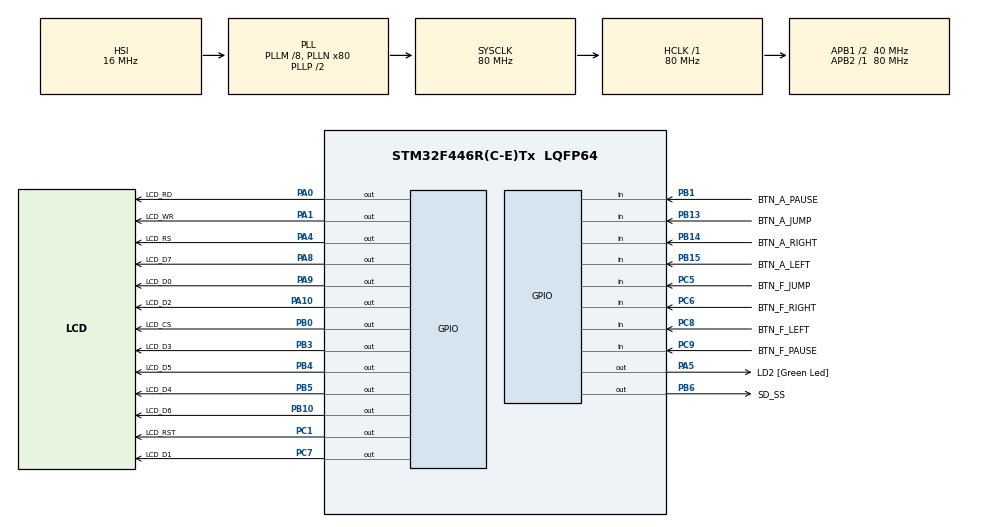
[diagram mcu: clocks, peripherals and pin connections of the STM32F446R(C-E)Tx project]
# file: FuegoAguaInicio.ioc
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Mcu.Family=STM32F4
Mcu.Name=STM32F446R(C-E)Tx
Mcu.Package=LQFP64
NVIC.PriorityGroup=NVIC_PRIORITYGROUP_0
PA0-WKUP.GPIO_Label=LCD_RD
PA0-WKUP.GPIO_Speed=GPIO_SPEED_FREQ_HIGH
PA0-WKUP.PinState=GPIO_PIN_SET
PA0-WKUP.Signal=GPIO_Output
PA1.GPIO_Label=LCD_WR
PA1.GPIO_Speed=GPIO_SPEED_FREQ_HIGH
PA1.PinState=GPIO_PIN_SET
PA1.Signal=GPIO_Output
PA10.GPIO_Label=LCD_D2
PA10.GPIO_Speed=GPIO_SPEED_FREQ_HIGH
PA10.Signal=GPIO_Output
PA13.GPIO_Label=TMS
PA13.Mode=Serial_Wire
PA13.Signal=SYS_JTMS-SWDIO
PA14.GPIO_Label=TCK
PA14.Mode=Serial_Wire
PA14.Signal=SYS_JTCK-SWCLK
PA2.GPIO_Label=USART_TX
PA2.Signal=USART2_TX
PA3.GPIO_Label=USART_RX
PA3.Signal=USART2_RX
PA4.GPIO_Label=LCD_RS
PA4.GPIO_Speed=GPIO_SPEED_FREQ_HIGH
PA4.Signal=GPIO_Output
PA5.GPIO_Label=LD2 [Green Led]
PA5.Signal=GPIO_Output
PA8.GPIO_Label=LCD_D7
PA8.GPIO_Speed=GPIO_SPEED_FREQ_HIGH
PA8.PinState=GPIO_PIN_RESET
PA8.Signal=GPIO_Output
PA9.GPIO_Label=LCD_D0
PA9.GPIO_Speed=GPIO_SPEED_FREQ_HIGH
PA9.Signal=GPIO_Output
PB0.GPIO_Label=LCD_CS
PB0.GPIO_Speed=GPIO_SPEED_FREQ_HIGH
PB0.PinState=GPIO_PIN_SET
PB0.Signal=GPIO_Output
PB1.GPIO_Label=BTN_A_PAUSE
PB1.GPIO_PuPd=GPIO_PULLUP
PB1.Signal=GPIO_Input
PB10.GPIO_Label=LCD_D6
PB10.GPIO_Speed=GPIO_SPEED_FREQ_HIGH
PB10.Signal=GPIO_Output
PB13.GPIO_Label=BTN_A_JUMP
PB13.GPIO_PuPd=GPIO_PULLUP
PB13.Signal=GPIO_Input
PB14.GPIO_Label=BTN_A_RIGHT
PB14.GPIO_PuPd=GPIO_PULLUP
PB14.Signal=GPIO_Input
PB15.GPIO_Label=BTN_A_LEFT
PB15.GPIO_PuPd=GPIO_PULLUP
PB15.Signal=GPIO_Input
PB3.GPIO_Label=LCD_D3
PB3.GPIO_Speed=GPIO_SPEED_FREQ_HIGH
PB3.Signal=GPIO_Output
PB4.GPIO_Label=LCD_D5
PB4.GPIO_Speed=GPIO_SPEED_FREQ_HIGH
PB4.Signal=GPIO_Output
PB5.GPIO_Label=LCD_D4
PB5.GPIO_Speed=GPIO_SPEED_FREQ_HIGH
PB5.Signal=GPIO_Output
PB6.GPIO_Label=SD_SS
PB6.GPIO_Speed=GPIO_SPEED_FREQ_HIGH
PB6.PinState=GPIO_PIN_SET
PB6.Signal=GPIO_Output
PC1.GPIO_Label=LCD_RST
PC1.GPIO_Speed=GPIO_SPEED_FREQ_HIGH
PC1.PinState=GPIO_PIN_SET
PC1.Signal=GPIO_Output
PC14-OSC32_IN.Signal=RCC_OSC32_IN
PC15-OSC32_OUT.Signal=RCC_OSC32_OUT
PC5.GPIO_Label=BTN_F_JUMP
PC5.GPIO_PuPd=GPIO_PULLUP
PC5.Signal=GPIO_Input
PC6.GPIO_Label=BTN_F_RIGHT
PC6.GPIO_PuPd=GPIO_PULLUP
PC6.Signal=GPIO_Input
PC7.GPIO_Label=LCD_D1
PC7.GPIO_Speed=GPIO_SPEED_FREQ_HIGH
PC7.Signal=GPIO_Output
PC8.GPIO_Label=BTN_F_LEFT
PC8.GPIO_PuPd=GPIO_PULLUP
PC8.Signal=GPIO_Input
PC9.GPIO_Label=BTN_F_PAUSE
PC9.GPIO_PuPd=GPIO_PULLUP
PC9.Signal=GPIO_Input
PH0-OSC_IN.Signal=RCC_OSC_IN
PH1-OSC_OUT.Signal=RCC_OSC_OUT
ProjectManager.HeapSize=0x200
ProjectManager.StackSize=0x400
ProjectManager.TargetToolchain=STM32CubeIDE
RCC.AHBFreq_Value=80000000
RCC.APB1CLKDivider=RCC_HCLK_DIV2
RCC.APB1Freq_Value=40000000
RCC.APB1TimFreq_Value=80000000
RCC.APB2Freq_Value=80000000
RCC.APB2TimFreq_Value=80000000
RCC.CortexFreq_Value=80000000
RCC.FLatency-AdvancedSettings=FLASH_LATENCY_2
RCC.HCLKFreq_Value=80000000
RCC.HSE_VALUE=8000000
RCC.HSI_VALUE=16000000
RCC.LSE_VALUE=32768
RCC.PLLM=8
RCC.PLLN=80
RCC.SYSCLKFreq_VALUE=80000000
RCC.SYSCLKSource=RCC_SYSCLKSOURCE_PLLCLK
RCC.USBFreq_Value=80000000
RCC.VCOOutputFreq_Value=160000000
board=NUCLEO-F446RE

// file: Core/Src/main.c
/* USER CODE BEGIN Header */
/**
  ******************************************************************************
  * @file           : main.c
  * @brief          : Main program body
  ******************************************************************************
  * @attention
  *
  * Copyright (c) 2026 STMicroelectronics.
  * All rights reserved.
  *
  * This software is licensed under terms that can be found in the LICENSE file
  * in the root directory of this software component.
  * If no LICENSE file comes with this software, it is provided AS-IS.
  *
  ******************************************************************************
  */
/* USER CODE END Header */
#include "main.h"

/* USER CODE BEGIN Includes */
#include "game_app.h"
#include "board_link.h"
#include "storage.h"
#include "ili9341.h"
#include "splash_images.h"
/* USER CODE END Includes */

/* USER CODE BEGIN PV */
volatile uint8_t nivel_elegido = 0U;
volatile uint8_t solicitud_jugar = 0U;
/* USER CODE END PV */

void SystemClock_Config(void);
static void MX_GPIO_Init(void);

int main(void)
{

  /* MCU Configuration--------------------------------------------------------*/

  /* Reset of all peripherals, Initializes the Flash interface and the Systick. */
  HAL_Init();

  /* Configure the system clock */
  SystemClock_Config();

  /* Initialize all configured peripherals */
  MX_GPIO_Init();
  /* USER CODE BEGIN 2 */
  BoardLink_Init();
  Storage_Init();
  GameApp_Init();
  /* USER CODE END 2 */

  /* Infinite loop */
  while (1)
  {

    /* USER CODE BEGIN 3 */
      if (GameApp_Poll())
      {
          nivel_elegido = GameApp_GetSelectedLevel();
          solicitud_jugar = 1U;
      }
  }
  /* USER CODE END 3 */
}

void SystemClock_Config(void)
{
  RCC_OscInitTypeDef RCC_OscInitStruct = {0};
  RCC_ClkInitTypeDef RCC_ClkInitStruct = {0};

  /** Configure the main internal regulator output voltage
  */
  __HAL_RCC_PWR_CLK_ENABLE();
  __HAL_PWR_VOLTAGESCALING_CONFIG(PWR_REGULATOR_VOLTAGE_SCALE3);

  /** Initializes the RCC Oscillators according to the specified parameters
  * in the RCC_OscInitTypeDef structure.
  */
  RCC_OscInitStruct.OscillatorType = RCC_OSCILLATORTYPE_HSI;
  RCC_OscInitStruct.HSIState = RCC_HSI_ON;
  RCC_OscInitStruct.HSICalibrationValue = RCC_HSICALIBRATION_DEFAULT;
  RCC_OscInitStruct.PLL.PLLState = RCC_PLL_ON;
  RCC_OscInitStruct.PLL.PLLSource = RCC_PLLSOURCE_HSI;
  RCC_OscInitStruct.PLL.PLLM = 8;
  RCC_OscInitStruct.PLL.PLLN = 80;
  RCC_OscInitStruct.PLL.PLLP = RCC_PLLP_DIV2;
  RCC_OscInitStruct.PLL.PLLQ = 2;
  RCC_OscInitStruct.PLL.PLLR = 2;
  if (HAL_RCC_OscConfig(&RCC_OscInitStruct) != HAL_OK)
  {
    Error_Handler();
  }

  /** Initializes the CPU, AHB and APB buses clocks
  */
  RCC_ClkInitStruct.ClockType = RCC_CLOCKTYPE_HCLK|RCC_CLOCKTYPE_SYSCLK
                              |RCC_CLOCKTYPE_PCLK1|RCC_CLOCKTYPE_PCLK2;
  RCC_ClkInitStruct.SYSCLKSource = RCC_SYSCLKSOURCE_PLLCLK;
  RCC_ClkInitStruct.AHBCLKDivider = RCC_SYSCLK_DIV1;
  RCC_ClkInitStruct.APB1CLKDivider = RCC_HCLK_DIV2;
  RCC_ClkInitStruct.APB2CLKDivider = RCC_HCLK_DIV1;

  if (HAL_RCC_ClockConfig(&RCC_ClkInitStruct, FLASH_LATENCY_2) != HAL_OK)
  {
    Error_Handler();
  }
}

static void MX_GPIO_Init(void)
{
  GPIO_InitTypeDef GPIO_InitStruct = {0};

  /* GPIO Ports Clock Enable */
  __HAL_RCC_GPIOC_CLK_ENABLE();
  __HAL_RCC_GPIOH_CLK_ENABLE();
  __HAL_RCC_GPIOA_CLK_ENABLE();
  __HAL_RCC_GPIOB_CLK_ENABLE();

  /*Configure GPIO pin Output Level */
  HAL_GPIO_WritePin(LCD_RST_GPIO_Port, LCD_RST_Pin, GPIO_PIN_SET);

  /*Configure GPIO pin Output Level */
  HAL_GPIO_WritePin(GPIOA, LCD_RD_Pin|LCD_WR_Pin, GPIO_PIN_SET);

  /*Configure GPIO pin Output Level */
  HAL_GPIO_WritePin(GPIOA, LCD_RS_Pin|LD2_Pin|LCD_D7_Pin|LCD_D0_Pin
                          |LCD_D2_Pin, GPIO_PIN_RESET);

  /*Configure GPIO pin Output Level */
  HAL_GPIO_WritePin(GPIOB, LCD_CS_Pin|SD_SS_Pin, GPIO_PIN_SET);

  /*Configure GPIO pin Output Level */
  HAL_GPIO_WritePin(GPIOB, LCD_D6_Pin|LCD_D3_Pin|LCD_D5_Pin|LCD_D4_Pin, GPIO_PIN_RESET);

  /*Configure GPIO pin Output Level */
  HAL_GPIO_WritePin(LCD_D1_GPIO_Port, LCD_D1_Pin, GPIO_PIN_RESET);

  /*Configure GPIO pins : LCD_RST_Pin LCD_D1_Pin */
  GPIO_InitStruct.Pin = LCD_RST_Pin|LCD_D1_Pin;
  GPIO_InitStruct.Mode = GPIO_MODE_OUTPUT_PP;
  GPIO_InitStruct.Pull = GPIO_NOPULL;
  GPIO_InitStruct.Speed = GPIO_SPEED_FREQ_HIGH;
  HAL_GPIO_Init(GPIOC, &GPIO_InitStruct);

  /*Configure GPIO pins : LCD_RD_Pin LCD_WR_Pin LCD_RS_Pin LCD_D7_Pin
                           LCD_D0_Pin LCD_D2_Pin */
  GPIO_InitStruct.Pin = LCD_RD_Pin|LCD_WR_Pin|LCD_RS_Pin|LCD_D7_Pin
                          |LCD_D0_Pin|LCD_D2_Pin;
  GPIO_InitStruct.Mode = GPIO_MODE_OUTPUT_PP;
  GPIO_InitStruct.Pull = GPIO_NOPULL;
  GPIO_InitStruct.Speed = GPIO_SPEED_FREQ_HIGH;
  HAL_GPIO_Init(GPIOA, &GPIO_InitStruct);

  /*Configure GPIO pins : USART_TX_Pin USART_RX_Pin */
  GPIO_InitStruct.Pin = USART_TX_Pin|USART_RX_Pin;
  GPIO_InitStruct.Mode = GPIO_MODE_AF_PP;
  GPIO_InitStruct.Pull = GPIO_NOPULL;
  GPIO_InitStruct.Speed = GPIO_SPEED_FREQ_VERY_HIGH;
  GPIO_InitStruct.Alternate = GPIO_AF7_USART2;
  HAL_GPIO_Init(GPIOA, &GPIO_InitStruct);

  /*Configure GPIO pin : LD2_Pin */
  GPIO_InitStruct.Pin = LD2_Pin;
  GPIO_InitStruct.Mode = GPIO_MODE_OUTPUT_PP;
  GPIO_InitStruct.Pull = GPIO_NOPULL;
  GPIO_InitStruct.Speed = GPIO_SPEED_FREQ_LOW;
  HAL_GPIO_Init(LD2_GPIO_Port, &GPIO_InitStruct);

  /*Configure GPIO pins : BTN_F_JUMP_Pin BTN_F_RIGHT_Pin BTN_F_LEFT_Pin BTN_F_PAUSE_Pin */
  GPIO_InitStruct.Pin = BTN_F_JUMP_Pin|BTN_F_RIGHT_Pin|BTN_F_LEFT_Pin|BTN_F_PAUSE_Pin;
  GPIO_InitStruct.Mode = GPIO_MODE_INPUT;
  GPIO_InitStruct.Pull = GPIO_PULLUP;
  HAL_GPIO_Init(GPIOC, &GPIO_InitStruct);

  /*Configure GPIO pins : LCD_CS_Pin LCD_D6_Pin LCD_D3_Pin LCD_D5_Pin
                           LCD_D4_Pin SD_SS_Pin */
  GPIO_InitStruct.Pin = LCD_CS_Pin|LCD_D6_Pin|LCD_D3_Pin|LCD_D5_Pin
                          |LCD_D4_Pin|SD_SS_Pin;
  GPIO_InitStruct.Mode = GPIO_MODE_OUTPUT_PP;
  GPIO_InitStruct.Pull = GPIO_NOPULL;
  GPIO_InitStruct.Speed = GPIO_SPEED_FREQ_HIGH;
  HAL_GPIO_Init(GPIOB, &GPIO_InitStruct);

  /*Configure GPIO pins : BTN_A_PAUSE_Pin BTN_A_JUMP_Pin BTN_A_RIGHT_Pin BTN_A_LEFT_Pin */
  GPIO_InitStruct.Pin = BTN_A_PAUSE_Pin|BTN_A_JUMP_Pin|BTN_A_RIGHT_Pin|BTN_A_LEFT_Pin;
  GPIO_InitStruct.Mode = GPIO_MODE_INPUT;
  GPIO_InitStruct.Pull = GPIO_PULLUP;
  HAL_GPIO_Init(GPIOB, &GPIO_InitStruct);

}

void Error_Handler(void)
{
  __disable_irq();
  while (1)
  {
  }
}
